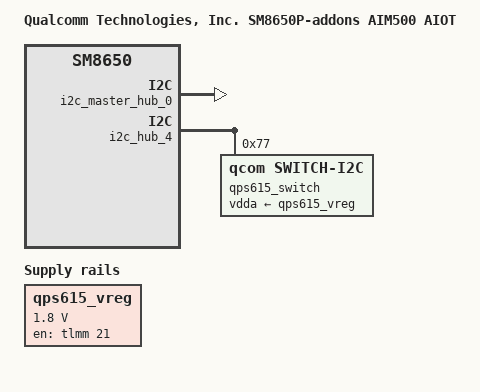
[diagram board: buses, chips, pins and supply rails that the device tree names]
// SPDX-License-Identifier: BSD-3-Clause
/*
 * Copyright (c) 2024 Qualcomm Innovation Center, Inc. All rights reserved.
 */

/dts-v1/;

#include "sm8650p-aim500-aiot.dts"
#include "sm8650p-addons.dtsi"


/ {
	model = "Qualcomm Technologies, Inc. SM8650P-addons AIM500 AIOT";
	compatible = "qcom,sm8650p-addons-aim500-aiot", "qcom,sm8650p-aim500", "qcom,sm8650p",
		     "qcom,sm8650";

	qps615_vreg: qps615-vreg {
		compatible = "regulator-fixed";
		regulator-name = "qps615_vreg";
		gpio = <&tlmm 21 GPIO_ACTIVE_HIGH>;
		regulator-min-microvolt = <1800000>;
		regulator-max-microvolt = <1800000>;
		enable-active-high;
		regulator-enable-ramp-delay = <10000>;
	};
};

&i2c_master_hub_0 {
	status = "okay";
};

&i2c_hub_4 {
	status = "okay";
	qps615_switch: pcie-switch@77 {
		compatible = "qcom,switch-i2c";
		reg = <0x77>;
		vdda-supply = <&qps615_vreg>;
		status = "okay";
	};
};

&pcie1 {
	dummy-supply = <&qps615_switch>;
};

&pcie1_phy {
	qcom,refclk-always-on;
};
